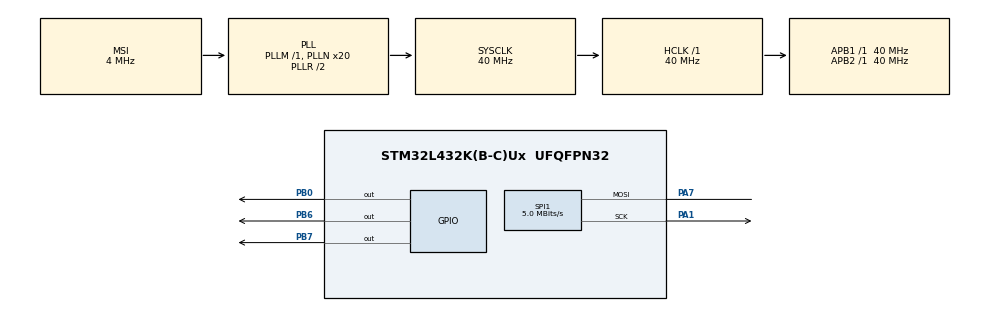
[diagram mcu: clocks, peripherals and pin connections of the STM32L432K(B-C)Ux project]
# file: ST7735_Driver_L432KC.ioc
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Mcu.Family=STM32L4
Mcu.Name=STM32L432K(B-C)Ux
Mcu.Package=UFQFPN32
NVIC.PriorityGroup=NVIC_PRIORITYGROUP_4
PA1.Mode=Simplex_Bidirectional_Master
PA1.Signal=SPI1_SCK
PA7.Mode=Simplex_Bidirectional_Master
PA7.Signal=SPI1_MOSI
PB0.Signal=GPIO_Output
PB6.Signal=GPIO_Output
PB7.Signal=GPIO_Output
ProjectManager.HeapSize=0x200
ProjectManager.StackSize=0x400
ProjectManager.TargetToolchain=STM32CubeIDE
RCC.AHBFreq_Value=40000000
RCC.APB1Freq_Value=40000000
RCC.APB1TimFreq_Value=40000000
RCC.APB2Freq_Value=40000000
RCC.APB2TimFreq_Value=40000000
RCC.CortexFreq_Value=40000000
RCC.HCLKFreq_Value=40000000
RCC.HSE_VALUE=8000000
RCC.HSI48_VALUE=48000000
RCC.HSI_VALUE=16000000
RCC.LSE_VALUE=32768
RCC.MSI_VALUE=4000000
RCC.PLLN=20
RCC.SYSCLKFreq_VALUE=40000000
RCC.SYSCLKSource=RCC_SYSCLKSOURCE_PLLCLK
RCC.VCOOutputFreq_Value=80000000
SPI1.BaudRatePrescaler=SPI_BAUDRATEPRESCALER_8
SPI1.CalculateBaudRate=5.0 MBits/s
SPI1.DataSize=SPI_DATASIZE_8BIT
SPI1.Direction=SPI_DIRECTION_1LINE
SPI1.Mode=SPI_MODE_MASTER
SPI1.VirtualType=VM_MASTER
board=custom

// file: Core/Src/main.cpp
/* USER CODE BEGIN Header */
/**
  ******************************************************************************
  * @file           : main.c
  * @brief          : Main program body
  ******************************************************************************
  * @attention
  *
  * Copyright (c) 2024 STMicroelectronics.
  * All rights reserved.
  *
  * This software is licensed under terms that can be found in the LICENSE file
  * in the root directory of this software component.
  * If no LICENSE file comes with this software, it is provided AS-IS.
  *
  ******************************************************************************
  */
/* USER CODE END Header */
#include "main.h"
#include "ST7735_Driver.h"

SPI_HandleTypeDef hspi1;

void SystemClock_Config(void);
static void MX_GPIO_Init(void);
static void MX_SPI1_Init(void);

int main(void)
{

  /* MCU Configuration--------------------------------------------------------*/

  /* Reset of all peripherals, Initializes the Flash interface and the Systick. */
  HAL_Init();

  /* Configure the system clock */
  SystemClock_Config();

  /* Initialize all configured peripherals */
  MX_GPIO_Init();
  MX_SPI1_Init();

  /* Infinite loop */
  /* USER CODE BEGIN WHILE */
  DisplayInit(&hspi1);
  DrawLine(0,64,159,64,ColorRatio(0.2, 0.3, 0.4));
  DrawLine(80,0,80,127,ColorRatio(0.2, 0.3, 0.4));
  DrawEllipse(0,0,159,127,ColorRatio(1, 0, 0));
  int gap = 0;
//  for(int i = 0; i < 10; i++){
//	  DrawCharacter(i + 65, i * 10 + gap, 10);
//	  gap++;
//  }
  WriteText("HELLO", sizeof("HELLO")/sizeof(char), 60, 40, ColorRatio(0,0,1), ColorRatio(0,1,0));
  HAL_Delay(1000);
//  DrawImage(ImageData);
  while (1)
  {
    /* USER CODE END WHILE */

  }
}

void SystemClock_Config(void)
{
  RCC_OscInitTypeDef RCC_OscInitStruct = {0};
  RCC_ClkInitTypeDef RCC_ClkInitStruct = {0};

  /** Configure the main internal regulator output voltage
  */
  if (HAL_PWREx_ControlVoltageScaling(PWR_REGULATOR_VOLTAGE_SCALE1) != HAL_OK)
  {
    Error_Handler();
  }

  /** Initializes the RCC Oscillators according to the specified parameters
  * in the RCC_OscInitTypeDef structure.
  */
  RCC_OscInitStruct.OscillatorType = RCC_OSCILLATORTYPE_MSI;
  RCC_OscInitStruct.MSIState = RCC_MSI_ON;
  RCC_OscInitStruct.MSICalibrationValue = 0;
  RCC_OscInitStruct.MSIClockRange = RCC_MSIRANGE_6;
  RCC_OscInitStruct.PLL.PLLState = RCC_PLL_ON;
  RCC_OscInitStruct.PLL.PLLSource = RCC_PLLSOURCE_MSI;
  RCC_OscInitStruct.PLL.PLLM = 1;
  RCC_OscInitStruct.PLL.PLLN = 20;
  RCC_OscInitStruct.PLL.PLLP = RCC_PLLP_DIV7;
  RCC_OscInitStruct.PLL.PLLQ = RCC_PLLQ_DIV2;
  RCC_OscInitStruct.PLL.PLLR = RCC_PLLR_DIV2;
  if (HAL_RCC_OscConfig(&RCC_OscInitStruct) != HAL_OK)
  {
    Error_Handler();
  }

  /** Initializes the CPU, AHB and APB buses clocks
  */
  RCC_ClkInitStruct.ClockType = RCC_CLOCKTYPE_HCLK|RCC_CLOCKTYPE_SYSCLK
                              |RCC_CLOCKTYPE_PCLK1|RCC_CLOCKTYPE_PCLK2;
  RCC_ClkInitStruct.SYSCLKSource = RCC_SYSCLKSOURCE_PLLCLK;
  RCC_ClkInitStruct.AHBCLKDivider = RCC_SYSCLK_DIV1;
  RCC_ClkInitStruct.APB1CLKDivider = RCC_HCLK_DIV1;
  RCC_ClkInitStruct.APB2CLKDivider = RCC_HCLK_DIV1;

  if (HAL_RCC_ClockConfig(&RCC_ClkInitStruct, FLASH_LATENCY_2) != HAL_OK)
  {
    Error_Handler();
  }
}

static void MX_SPI1_Init(void)
{

  /* SPI1 parameter configuration*/
  hspi1.Instance = SPI1;
  hspi1.Init.Mode = SPI_MODE_MASTER;
  hspi1.Init.Direction = SPI_DIRECTION_1LINE;
  hspi1.Init.DataSize = SPI_DATASIZE_8BIT;
  hspi1.Init.CLKPolarity = SPI_POLARITY_LOW;
  hspi1.Init.CLKPhase = SPI_PHASE_1EDGE;
  hspi1.Init.NSS = SPI_NSS_SOFT;
  hspi1.Init.BaudRatePrescaler = SPI_BAUDRATEPRESCALER_8;
  hspi1.Init.FirstBit = SPI_FIRSTBIT_MSB;
  hspi1.Init.TIMode = SPI_TIMODE_DISABLE;
  hspi1.Init.CRCCalculation = SPI_CRCCALCULATION_DISABLE;
  hspi1.Init.CRCPolynomial = 7;
  hspi1.Init.CRCLength = SPI_CRC_LENGTH_DATASIZE;
  hspi1.Init.NSSPMode = SPI_NSS_PULSE_ENABLE;
  if (HAL_SPI_Init(&hspi1) != HAL_OK)
  {
    Error_Handler();
  }

}

static void MX_GPIO_Init(void)
{
  GPIO_InitTypeDef GPIO_InitStruct = {0};

  /* GPIO Ports Clock Enable */
  __HAL_RCC_GPIOA_CLK_ENABLE();
  __HAL_RCC_GPIOB_CLK_ENABLE();

  /*Configure GPIO pin Output Level */
  HAL_GPIO_WritePin(GPIOB, GPIO_PIN_0|GPIO_PIN_6|GPIO_PIN_7, GPIO_PIN_RESET);

  /*Configure GPIO pins : PB0 PB6 PB7 */
  GPIO_InitStruct.Pin = GPIO_PIN_0|GPIO_PIN_6|GPIO_PIN_7;
  GPIO_InitStruct.Mode = GPIO_MODE_OUTPUT_PP;
  GPIO_InitStruct.Pull = GPIO_NOPULL;
  GPIO_InitStruct.Speed = GPIO_SPEED_FREQ_LOW;
  HAL_GPIO_Init(GPIOB, &GPIO_InitStruct);

}

void Error_Handler(void)
{
  __disable_irq();
  while (1)
  {
  }
}
